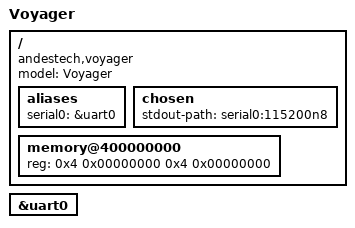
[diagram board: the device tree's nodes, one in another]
// SPDX-License-Identifier: GPL-2.0 OR MIT
/*
 * Copyright (C) 2025 Andes Technology Corporation. All rights reserved.
 */

#include "qilai.dtsi"

/ {
	model = "Voyager";
	compatible = "andestech,voyager", "andestech,qilai";

	aliases {
		serial0 = &uart0;
	};

	chosen {
		stdout-path = "serial0:115200n8";
	};

	memory@400000000 {
		device_type = "memory";
		reg = <0x4 0x00000000 0x4 0x00000000>;
	};
};

&uart0 {
	status = "okay";
};
